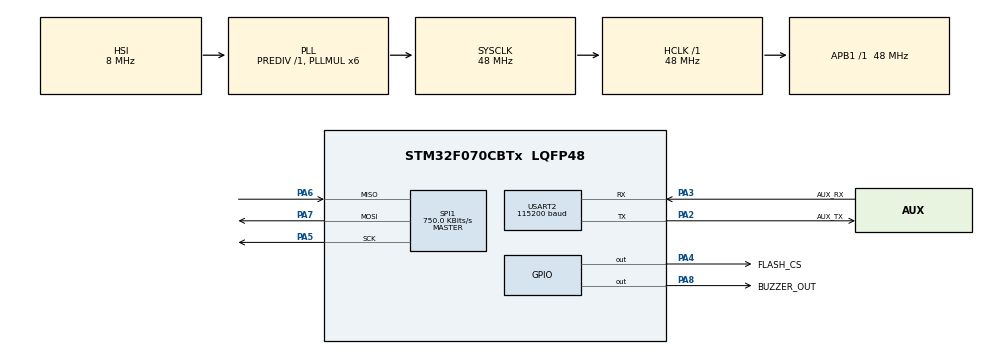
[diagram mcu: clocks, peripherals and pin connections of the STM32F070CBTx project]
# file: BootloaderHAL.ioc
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IWDG.Prescaler=IWDG_PRESCALER_64
Mcu.Family=STM32F0
Mcu.Name=STM32F070CBTx
Mcu.Package=LQFP48
NVIC.USART2_IRQn=true\:0\:0\:false\:false\:true\:true\:true
PA13.Mode=Serial_Wire
PA13.Signal=SYS_SWDIO
PA14.Mode=Serial_Wire
PA14.Signal=SYS_SWCLK
PA2.GPIO_Label=AUX_TX
PA2.Mode=Asynchronous
PA2.Signal=USART2_TX
PA3.GPIO_Label=AUX_RX
PA3.Mode=Asynchronous
PA3.Signal=USART2_RX
PA4.GPIO_Label=FLASH_CS
PA4.Signal=GPIO_Output
PA5.Mode=Full_Duplex_Master
PA5.Signal=SPI1_SCK
PA6.Mode=Full_Duplex_Master
PA6.Signal=SPI1_MISO
PA7.Mode=Full_Duplex_Master
PA7.Signal=SPI1_MOSI
PA8.GPIO_Label=BUZZER_OUT
PA8.Signal=GPIO_Output
PF0-OSC_IN.Mode=HSE-External-Oscillator
PF0-OSC_IN.Signal=RCC_OSC_IN
PF1-OSC_OUT.Mode=HSE-External-Oscillator
PF1-OSC_OUT.Signal=RCC_OSC_OUT
ProjectManager.HeapSize=0x200
ProjectManager.StackSize=0x400
ProjectManager.TargetToolchain=EWARM V8
RCC.AHBFreq_Value=48000000
RCC.APB1Freq_Value=48000000
RCC.APB1TimFreq_Value=48000000
RCC.HCLKFreq_Value=48000000
RCC.PLLMUL=RCC_PLL_MUL6
RCC.SYSCLKFreq_VALUE=48000000
RCC.SYSCLKSource=RCC_SYSCLKSOURCE_PLLCLK
SPI1.BaudRatePrescaler=SPI_BAUDRATEPRESCALER_64
SPI1.CalculateBaudRate=750.0 KBits/s
SPI1.DataSize=SPI_DATASIZE_8BIT
SPI1.Direction=SPI_DIRECTION_2LINES
SPI1.Mode=SPI_MODE_MASTER
SPI1.VirtualType=VM_MASTER
USART2.BaudRate=115200
USART2.VirtualMode-Asynchronous=VM_ASYNC
VP_IWDG_VS_IWDG.Mode=IWDG_Activate
board=custom

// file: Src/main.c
/* USER CODE BEGIN Header */
/**
  ******************************************************************************
  * @file           : main.c
  * @brief          : Main program body
  ******************************************************************************
  * @attention
  *
  * <h2><center>&copy; Copyright (c) 2019 STMicroelectronics.
  * All rights reserved.</center></h2>
  *
  * This software component is licensed by ST under BSD 3-Clause license,
  * the "License"; You may not use this file except in compliance with the
  * License. You may obtain a copy of the License at:
  *                        opensource.org/licenses/BSD-3-Clause
  *
  ******************************************************************************
  */
/* USER CODE END Header */

#include "main.h"

/* USER CODE BEGIN Includes */
#include "bootloader.h"
/* USER CODE END Includes */

IWDG_HandleTypeDef hiwdg;

SPI_HandleTypeDef hspi1;

UART_HandleTypeDef huart2;

void SystemClock_Config(void);
static void MX_GPIO_Init(void);
void MX_IWDG_Init(void);
static void MX_SPI1_Init(void);
static void MX_USART2_UART_Init(void);

int main(void)
{

  /* MCU Configuration--------------------------------------------------------*/

  /* Reset of all peripherals, Initializes the Flash interface and the Systick. */
  HAL_Init();

  /* Configure the system clock */
  SystemClock_Config();

  /* Initialize all configured peripherals */
  MX_GPIO_Init();
  //MX_IWDG_Init();
  MX_SPI1_Init();
  MX_USART2_UART_Init();
  /* USER CODE BEGIN 2 */
  bootloaderSetup();
  //We shouldn't exit from above function
  /* USER CODE END 2 */

  /* Infinite loop */
  while (1)
  {

  }
}

void SystemClock_Config(void)
{
  RCC_OscInitTypeDef RCC_OscInitStruct = {0};
  RCC_ClkInitTypeDef RCC_ClkInitStruct = {0};

  /** Initializes the CPU, AHB and APB busses clocks
  */
  RCC_OscInitStruct.OscillatorType = RCC_OSCILLATORTYPE_HSI|RCC_OSCILLATORTYPE_LSI;
  RCC_OscInitStruct.HSIState = RCC_HSI_ON;
  RCC_OscInitStruct.HSICalibrationValue = RCC_HSICALIBRATION_DEFAULT;
  RCC_OscInitStruct.LSIState = RCC_LSI_ON;
  RCC_OscInitStruct.PLL.PLLState = RCC_PLL_ON;
  RCC_OscInitStruct.PLL.PLLSource = RCC_PLLSOURCE_HSI;
  RCC_OscInitStruct.PLL.PLLMUL = RCC_PLL_MUL6;
  RCC_OscInitStruct.PLL.PREDIV = RCC_PREDIV_DIV1;
  if (HAL_RCC_OscConfig(&RCC_OscInitStruct) != HAL_OK)
  {
    Error_Handler();
  }
  /** Initializes the CPU, AHB and APB busses clocks
  */
  RCC_ClkInitStruct.ClockType = RCC_CLOCKTYPE_HCLK|RCC_CLOCKTYPE_SYSCLK
                              |RCC_CLOCKTYPE_PCLK1;
  RCC_ClkInitStruct.SYSCLKSource = RCC_SYSCLKSOURCE_PLLCLK;
  RCC_ClkInitStruct.AHBCLKDivider = RCC_SYSCLK_DIV1;
  RCC_ClkInitStruct.APB1CLKDivider = RCC_HCLK_DIV1;

  if (HAL_RCC_ClockConfig(&RCC_ClkInitStruct, FLASH_LATENCY_1) != HAL_OK)
  {
    Error_Handler();
  }
}

void MX_IWDG_Init(void)
{

  hiwdg.Instance = IWDG;
  hiwdg.Init.Prescaler = IWDG_PRESCALER_64;
  hiwdg.Init.Window = 4095;
  hiwdg.Init.Reload = 4095;
  if (HAL_IWDG_Init(&hiwdg) != HAL_OK)
  {
    Error_Handler();
  }

}

static void MX_SPI1_Init(void)
{

  /* SPI1 parameter configuration*/
  hspi1.Instance = SPI1;
  hspi1.Init.Mode = SPI_MODE_MASTER;
  hspi1.Init.Direction = SPI_DIRECTION_2LINES;
  hspi1.Init.DataSize = SPI_DATASIZE_8BIT;
  hspi1.Init.CLKPolarity = SPI_POLARITY_LOW;
  hspi1.Init.CLKPhase = SPI_PHASE_1EDGE;
  hspi1.Init.NSS = SPI_NSS_SOFT;
  hspi1.Init.BaudRatePrescaler = SPI_BAUDRATEPRESCALER_64;
  hspi1.Init.FirstBit = SPI_FIRSTBIT_MSB;
  hspi1.Init.TIMode = SPI_TIMODE_DISABLE;
  hspi1.Init.CRCCalculation = SPI_CRCCALCULATION_DISABLE;
  hspi1.Init.CRCPolynomial = 7;
  hspi1.Init.CRCLength = SPI_CRC_LENGTH_DATASIZE;
  hspi1.Init.NSSPMode = SPI_NSS_PULSE_ENABLE;
  if (HAL_SPI_Init(&hspi1) != HAL_OK)
  {
    Error_Handler();
  }
  /* USER CODE BEGIN SPI1_Init 2 */
  __HAL_SPI_ENABLE(&hspi1);
  /* USER CODE END SPI1_Init 2 */

}

static void MX_USART2_UART_Init(void)
{

  huart2.Instance = USART2;
  huart2.Init.BaudRate = 115200;
  huart2.Init.WordLength = UART_WORDLENGTH_8B;
  huart2.Init.StopBits = UART_STOPBITS_1;
  huart2.Init.Parity = UART_PARITY_NONE;
  huart2.Init.Mode = UART_MODE_TX_RX;
  huart2.Init.HwFlowCtl = UART_HWCONTROL_NONE;
  huart2.Init.OverSampling = UART_OVERSAMPLING_16;
  huart2.Init.OneBitSampling = UART_ONE_BIT_SAMPLE_DISABLE;
  huart2.AdvancedInit.AdvFeatureInit = UART_ADVFEATURE_NO_INIT;
  if (HAL_UART_Init(&huart2) != HAL_OK)
  {
    Error_Handler();
  }

}

static void MX_GPIO_Init(void)
{
  GPIO_InitTypeDef GPIO_InitStruct = {0};

  /* GPIO Ports Clock Enable */
  __HAL_RCC_GPIOF_CLK_ENABLE();
  __HAL_RCC_GPIOA_CLK_ENABLE();

  /*Configure GPIO pin Output Level */
  HAL_GPIO_WritePin(GPIOA, FLASH_CS_Pin|BUZZER_OUT_Pin, GPIO_PIN_RESET);

  /*Configure GPIO pins : FLASH_CS_Pin BUZZER_OUT_Pin */
  GPIO_InitStruct.Pin = FLASH_CS_Pin|BUZZER_OUT_Pin;
  GPIO_InitStruct.Mode = GPIO_MODE_OUTPUT_PP;
  GPIO_InitStruct.Pull = GPIO_NOPULL;
  GPIO_InitStruct.Speed = GPIO_SPEED_FREQ_LOW;
  HAL_GPIO_Init(GPIOA, &GPIO_InitStruct);

}

void Error_Handler(void)
{
}

/************************ (C) COPYRIGHT STMicroelectronics *****END OF FILE****/
